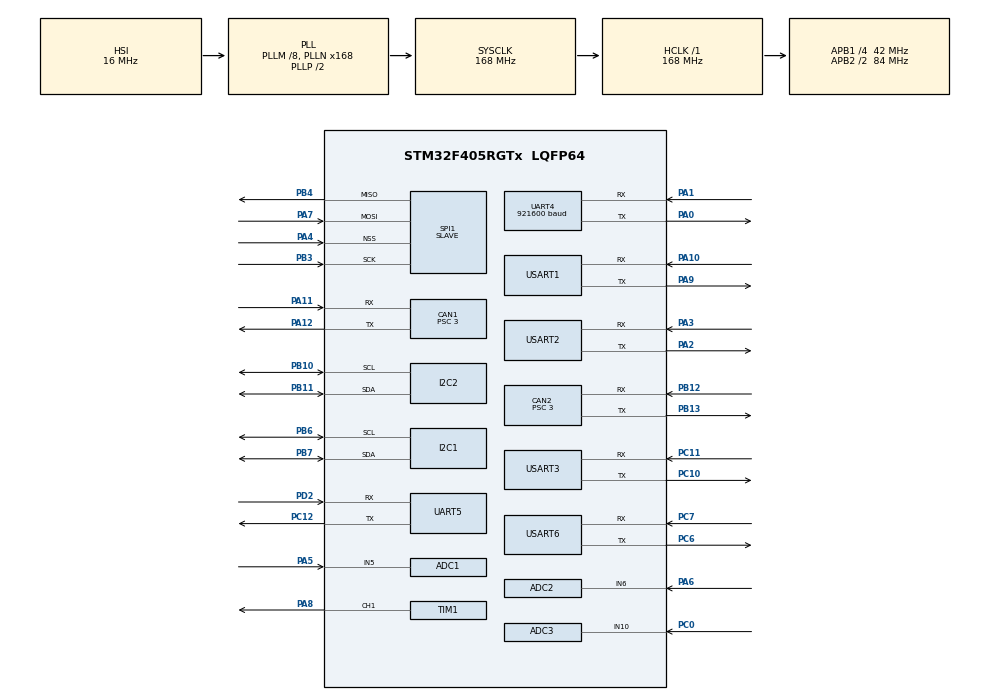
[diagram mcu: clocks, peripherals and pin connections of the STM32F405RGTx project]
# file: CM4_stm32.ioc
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ADC1.Channel-2\#ChannelRegularConversion=ADC_CHANNEL_5
ADC1.NbrOfConversionFlag=1
ADC1.Rank-2\#ChannelRegularConversion=1
ADC1.SamplingTime-2\#ChannelRegularConversion=ADC_SAMPLETIME_3CYCLES
ADC1.master=1
ADC2.Channel-2\#ChannelRegularConversion=ADC_CHANNEL_6
ADC2.NbrOfConversionFlag=1
ADC2.Rank-2\#ChannelRegularConversion=1
ADC2.SamplingTime-2\#ChannelRegularConversion=ADC_SAMPLETIME_3CYCLES
ADC3.Channel-2\#ChannelRegularConversion=ADC_CHANNEL_10
ADC3.NbrOfConversionFlag=1
ADC3.Rank-2\#ChannelRegularConversion=1
ADC3.SamplingTime-2\#ChannelRegularConversion=ADC_SAMPLETIME_3CYCLES
CAN1.BS1=CAN_BS1_9TQ
CAN1.BS2=CAN_BS2_4TQ
CAN1.CalculateBaudRate=1000000
CAN1.CalculateTimeBit=1000
CAN1.CalculateTimeQuantum=71.42857142857143
CAN1.Prescaler=3
CAN1.TXFP=ENABLE
CAN2.BS1=CAN_BS1_9TQ
CAN2.BS2=CAN_BS2_4TQ
CAN2.CalculateBaudRate=1000000
CAN2.CalculateTimeBit=1000
CAN2.CalculateTimeQuantum=71.42857142857143
CAN2.Prescaler=3
CAN2.TXFP=ENABLE
Dma.Request0=USART6_RX
Dma.Request1=USART1_RX
Dma.Request2=UART4_RX
Dma.Request3=SPI1_RX
Dma.Request4=SPI1_TX
Dma.SPI1_RX.3.Direction=DMA_PERIPH_TO_MEMORY
Dma.SPI1_RX.3.FIFOMode=DMA_FIFOMODE_DISABLE
Dma.SPI1_RX.3.Instance=DMA2_Stream2
Dma.SPI1_RX.3.MemDataAlignment=DMA_MDATAALIGN_BYTE
Dma.SPI1_RX.3.MemInc=DMA_MINC_ENABLE
Dma.SPI1_RX.3.Mode=DMA_NORMAL
Dma.SPI1_RX.3.PeriphDataAlignment=DMA_PDATAALIGN_BYTE
Dma.SPI1_RX.3.PeriphInc=DMA_PINC_DISABLE
Dma.SPI1_RX.3.Priority=DMA_PRIORITY_HIGH
Dma.SPI1_TX.4.Direction=DMA_MEMORY_TO_PERIPH
Dma.SPI1_TX.4.FIFOMode=DMA_FIFOMODE_DISABLE
Dma.SPI1_TX.4.Instance=DMA2_Stream3
Dma.SPI1_TX.4.MemDataAlignment=DMA_MDATAALIGN_BYTE
Dma.SPI1_TX.4.MemInc=DMA_MINC_ENABLE
Dma.SPI1_TX.4.Mode=DMA_NORMAL
Dma.SPI1_TX.4.PeriphDataAlignment=DMA_PDATAALIGN_BYTE
Dma.SPI1_TX.4.PeriphInc=DMA_PINC_DISABLE
Dma.SPI1_TX.4.Priority=DMA_PRIORITY_HIGH
Dma.UART4_RX.2.Direction=DMA_PERIPH_TO_MEMORY
Dma.UART4_RX.2.FIFOMode=DMA_FIFOMODE_DISABLE
Dma.UART4_RX.2.Instance=DMA1_Stream2
Dma.UART4_RX.2.MemDataAlignment=DMA_MDATAALIGN_BYTE
Dma.UART4_RX.2.MemInc=DMA_MINC_ENABLE
Dma.UART4_RX.2.Mode=DMA_NORMAL
Dma.UART4_RX.2.PeriphDataAlignment=DMA_PDATAALIGN_BYTE
Dma.UART4_RX.2.PeriphInc=DMA_PINC_DISABLE
Dma.UART4_RX.2.Priority=DMA_PRIORITY_MEDIUM
Dma.USART1_RX.1.Direction=DMA_PERIPH_TO_MEMORY
Dma.USART1_RX.1.FIFOMode=DMA_FIFOMODE_DISABLE
Dma.USART1_RX.1.Instance=DMA2_Stream5
Dma.USART1_RX.1.MemDataAlignment=DMA_MDATAALIGN_BYTE
Dma.USART1_RX.1.MemInc=DMA_MINC_ENABLE
Dma.USART1_RX.1.Mode=DMA_NORMAL
Dma.USART1_RX.1.PeriphDataAlignment=DMA_PDATAALIGN_BYTE
Dma.USART1_RX.1.PeriphInc=DMA_PINC_DISABLE
Dma.USART1_RX.1.Priority=DMA_PRIORITY_HIGH
Dma.USART6_RX.0.Direction=DMA_PERIPH_TO_MEMORY
Dma.USART6_RX.0.FIFOMode=DMA_FIFOMODE_DISABLE
Dma.USART6_RX.0.Instance=DMA2_Stream1
Dma.USART6_RX.0.MemDataAlignment=DMA_MDATAALIGN_BYTE
Dma.USART6_RX.0.MemInc=DMA_MINC_ENABLE
Dma.USART6_RX.0.Mode=DMA_NORMAL
Dma.USART6_RX.0.PeriphDataAlignment=DMA_PDATAALIGN_BYTE
Dma.USART6_RX.0.PeriphInc=DMA_PINC_DISABLE
Dma.USART6_RX.0.Priority=DMA_PRIORITY_HIGH
IWDG.Prescaler=IWDG_PRESCALER_16
IWDG.Reload=500
Mcu.Family=STM32F4
Mcu.Name=STM32F405RGTx
Mcu.Package=LQFP64
NVIC.CAN1_RX0_IRQn=true\:0\:0\:false\:false\:true\:true\:true\:true
NVIC.CAN1_TX_IRQn=true\:0\:0\:false\:false\:true\:true\:true\:true
NVIC.CAN2_RX1_IRQn=true\:1\:0\:true\:false\:true\:true\:true\:true
NVIC.CAN2_TX_IRQn=true\:0\:0\:false\:false\:true\:true\:true\:true
NVIC.DMA1_Stream2_IRQn=true\:1\:0\:true\:false\:true\:false\:true\:true
NVIC.DMA2_Stream1_IRQn=true\:1\:0\:true\:false\:true\:false\:true\:true
NVIC.DMA2_Stream2_IRQn=true\:0\:0\:true\:false\:true\:false\:true\:true
NVIC.DMA2_Stream3_IRQn=true\:0\:0\:false\:false\:true\:false\:true\:true
NVIC.DMA2_Stream5_IRQn=true\:1\:0\:true\:false\:true\:false\:true\:true
NVIC.PriorityGroup=NVIC_PRIORITYGROUP_4
NVIC.TIM2_IRQn=true\:2\:0\:true\:false\:true\:true\:true\:true
NVIC.USART6_IRQn=true\:0\:0\:false\:false\:true\:true\:true\:true
PA0-WKUP.Mode=Asynchronous
PA0-WKUP.Signal=UART4_TX
PA1.Mode=Asynchronous
PA1.Signal=UART4_RX
PA10.Mode=Asynchronous
PA10.Signal=USART1_RX
PA11.Mode=CAN_Activate
PA11.Signal=CAN1_RX
PA12.Mode=CAN_Activate
PA12.Signal=CAN1_TX
PA13.Mode=Serial_Wire
PA13.Signal=SYS_JTMS-SWDIO
PA14.Mode=Serial_Wire
PA14.Signal=SYS_JTCK-SWCLK
PA2.Mode=Asynchronous
PA2.Signal=USART2_TX
PA3.Mode=Asynchronous
PA3.Signal=USART2_RX
PA4.Mode=NSS_Signal_Hard_Input
PA4.Signal=SPI1_NSS
PA5.Signal=ADCx_IN5
PA6.Signal=ADCx_IN6
PA7.Mode=Full_Duplex_Slave
PA7.Signal=SPI1_MOSI
PA8.Signal=S_TIM1_CH1
PA9.Mode=Asynchronous
PA9.Signal=USART1_TX
PB10.Mode=I2C
PB10.Signal=I2C2_SCL
PB11.Mode=I2C
PB11.Signal=I2C2_SDA
PB12.Mode=CAN_Activate
PB12.Signal=CAN2_RX
PB13.Mode=CAN_Activate
PB13.Signal=CAN2_TX
PB3.Mode=Full_Duplex_Slave
PB3.Signal=SPI1_SCK
PB4.Mode=Full_Duplex_Slave
PB4.Signal=SPI1_MISO
PB6.Mode=I2C
PB6.Signal=I2C1_SCL
PB7.Mode=I2C
PB7.Signal=I2C1_SDA
PC0.Signal=ADCx_IN10
PC10.Mode=Asynchronous
PC10.Signal=USART3_TX
PC11.Mode=Asynchronous
PC11.Signal=USART3_RX
PC12.Mode=Asynchronous
PC12.Signal=UART5_TX
PC14-OSC32_IN.Mode=LSE-External-Oscillator
PC14-OSC32_IN.Signal=RCC_OSC32_IN
PC15-OSC32_OUT.Mode=LSE-External-Oscillator
PC15-OSC32_OUT.Signal=RCC_OSC32_OUT
PC6.Mode=Asynchronous
PC6.Signal=USART6_TX
PC7.Mode=Asynchronous
PC7.Signal=USART6_RX
PD2.Mode=Asynchronous
PD2.Signal=UART5_RX
PH0-OSC_IN.Mode=HSE-External-Oscillator
PH0-OSC_IN.Signal=RCC_OSC_IN
PH1-OSC_OUT.Mode=HSE-External-Oscillator
PH1-OSC_OUT.Signal=RCC_OSC_OUT
ProjectManager.HeapSize=0x200
ProjectManager.StackSize=0x400
ProjectManager.TargetToolchain=CMake
RCC.48MHZClocksFreq_Value=84000000
RCC.AHBFreq_Value=168000000
RCC.APB1CLKDivider=RCC_HCLK_DIV4
RCC.APB1Freq_Value=42000000
RCC.APB1TimFreq_Value=84000000
RCC.APB2CLKDivider=RCC_HCLK_DIV2
RCC.APB2Freq_Value=84000000
RCC.APB2TimFreq_Value=168000000
RCC.CortexFreq_Value=168000000
RCC.HCLKFreq_Value=168000000
RCC.HSE_VALUE=8000000
RCC.HSI_VALUE=16000000
RCC.PLLM=8
RCC.PLLN=168
RCC.SYSCLKFreq_VALUE=168000000
RCC.SYSCLKSource=RCC_SYSCLKSOURCE_PLLCLK
RCC.VCOOutputFreq_Value=336000000
SH.ADCx_IN10.0=ADC3_IN10,IN10
SH.ADCx_IN5.0=ADC1_IN5,IN5
SH.ADCx_IN6.0=ADC2_IN6,IN6
SH.S_TIM1_CH1.0=TIM1_CH1,PWM Generation1 CH1
SPI1.DataSize=SPI_DATASIZE_8BIT
SPI1.Direction=SPI_DIRECTION_2LINES
SPI1.Mode=SPI_MODE_SLAVE
SPI1.VirtualNSS=VM_NSSHARD
SPI1.VirtualType=VM_SLAVE
TIM1.Channel-PWM\ Generation1\ CH1=TIM_CHANNEL_1
TIM2.Period=1000-1
TIM2.Prescaler=84
UART4.BaudRate=921600
UART4.VirtualMode=Asynchronous
UART5.VirtualMode=Asynchronous
USART1.OverSampling=UART_OVERSAMPLING_8
USART1.VirtualMode=VM_ASYNC
USART2.VirtualMode=VM_ASYNC
USART3.VirtualMode=VM_ASYNC
USART6.VirtualMode=VM_ASYNC
VP_IWDG_VS_IWDG.Mode=IWDG_Activate
VP_TIM1_VS_ClockSourceINT.Mode=Internal
VP_TIM2_VS_ClockSourceINT.Mode=Internal
board=custom

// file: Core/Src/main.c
/* USER CODE BEGIN Header */
/**
 ******************************************************************************
 * @file           : main.c
 * @brief          : Main program body
 ******************************************************************************
 * @attention
 *
 * Copyright (c) 2024 STMicroelectronics.
 * All rights reserved.
 *
 * This software is licensed under terms that can be found in the LICENSE file
 * in the root directory of this software component.
 * If no LICENSE file comes with this software, it is provided AS-IS.
 *
 ******************************************************************************
 */
/* USER CODE END Header */
#include "main.h"
#include "adc.h"
#include "can.h"
#include "dma.h"
#include "i2c.h"
#include "iwdg.h"
#include "spi.h"
#include "tim.h"
#include "usart.h"
#include "gpio.h"

/* USER CODE BEGIN Includes */
#include "task_init.h"
/* USER CODE END Includes */

void SystemClock_Config(void);

int main(void)
{

  /* MCU Configuration--------------------------------------------------------*/

  /* Reset of all peripherals, Initializes the Flash interface and the Systick. */
  HAL_Init();

  /* Configure the system clock */
  SystemClock_Config();

  /* Initialize all configured peripherals */
  MX_GPIO_Init();
  MX_DMA_Init();
  MX_ADC1_Init();
  MX_ADC2_Init();
  MX_ADC3_Init();
  MX_CAN1_Init();
  MX_CAN2_Init();
  MX_I2C1_Init();
  MX_I2C2_Init();
  MX_SPI1_Init();
  MX_UART5_Init();
  MX_USART1_UART_Init();
  MX_USART2_UART_Init();
  MX_USART3_UART_Init();
  MX_USART6_UART_Init();
  MX_TIM2_Init();
  MX_UART4_Init();
  //MX_IWDG_Init();
  MX_TIM1_Init();
  /* USER CODE BEGIN 2 */

  task_init();

  /* USER CODE END 2 */

  /* Infinite loop */
  while (1)
  {

  }
}

void SystemClock_Config(void)
{
  RCC_OscInitTypeDef RCC_OscInitStruct = {0};
  RCC_ClkInitTypeDef RCC_ClkInitStruct = {0};

  /** Configure the main internal regulator output voltage
  */
  __HAL_RCC_PWR_CLK_ENABLE();
  __HAL_PWR_VOLTAGESCALING_CONFIG(PWR_REGULATOR_VOLTAGE_SCALE1);

  /** Initializes the RCC Oscillators according to the specified parameters
  * in the RCC_OscInitTypeDef structure.
  */
  RCC_OscInitStruct.OscillatorType = RCC_OSCILLATORTYPE_HSI|RCC_OSCILLATORTYPE_LSI;
  RCC_OscInitStruct.HSIState = RCC_HSI_ON;
  RCC_OscInitStruct.HSICalibrationValue = RCC_HSICALIBRATION_DEFAULT;
  RCC_OscInitStruct.LSIState = RCC_LSI_ON;
  RCC_OscInitStruct.PLL.PLLState = RCC_PLL_ON;
  RCC_OscInitStruct.PLL.PLLSource = RCC_PLLSOURCE_HSI;
  RCC_OscInitStruct.PLL.PLLM = 8;
  RCC_OscInitStruct.PLL.PLLN = 168;
  RCC_OscInitStruct.PLL.PLLP = RCC_PLLP_DIV2;
  RCC_OscInitStruct.PLL.PLLQ = 4;
  if (HAL_RCC_OscConfig(&RCC_OscInitStruct) != HAL_OK)
  {
    Error_Handler();
  }

  /** Initializes the CPU, AHB and APB buses clocks
  */
  RCC_ClkInitStruct.ClockType = RCC_CLOCKTYPE_HCLK|RCC_CLOCKTYPE_SYSCLK
                              |RCC_CLOCKTYPE_PCLK1|RCC_CLOCKTYPE_PCLK2;
  RCC_ClkInitStruct.SYSCLKSource = RCC_SYSCLKSOURCE_PLLCLK;
  RCC_ClkInitStruct.AHBCLKDivider = RCC_SYSCLK_DIV1;
  RCC_ClkInitStruct.APB1CLKDivider = RCC_HCLK_DIV4;
  RCC_ClkInitStruct.APB2CLKDivider = RCC_HCLK_DIV2;

  if (HAL_RCC_ClockConfig(&RCC_ClkInitStruct, FLASH_LATENCY_5) != HAL_OK)
  {
    Error_Handler();
  }
}

void Error_Handler(void)
{
  __disable_irq();
  while (1)
  {
  }
}
